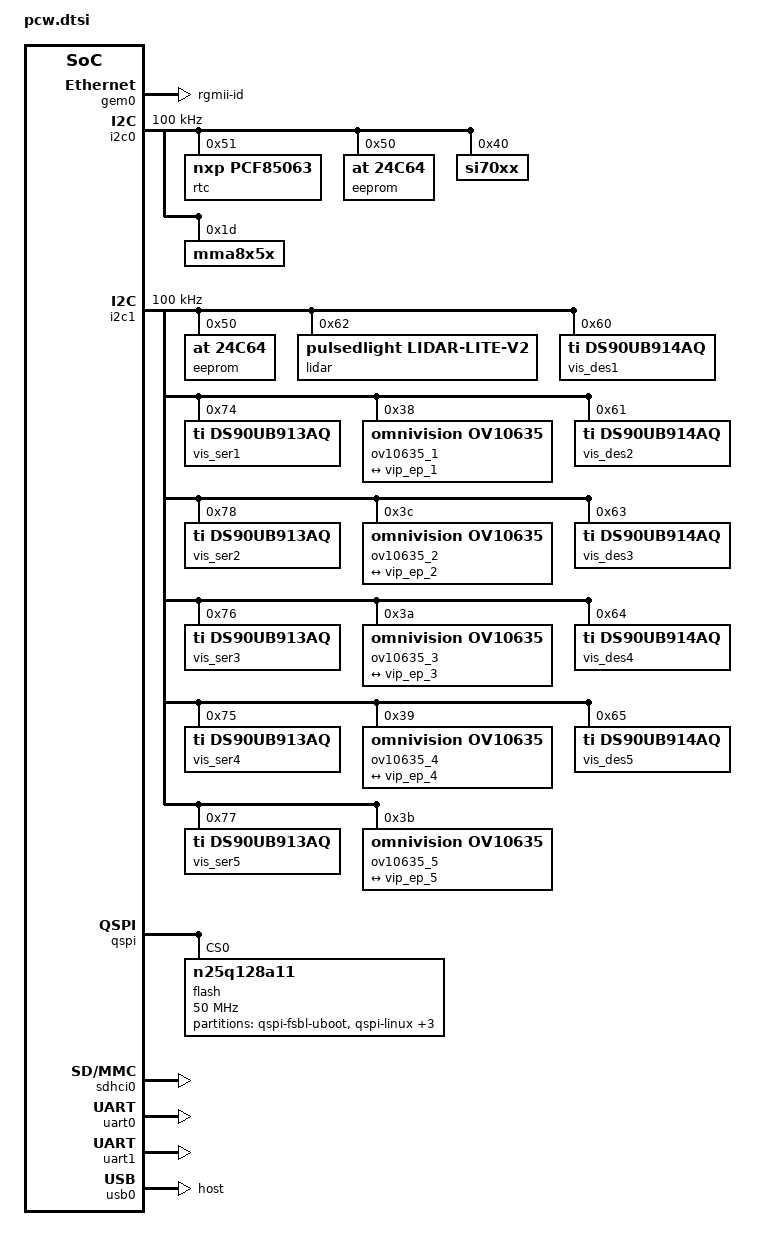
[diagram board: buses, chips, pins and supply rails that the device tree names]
/*
 * CAUTION: This file is automatically generated by Xilinx.
 * Version:  
 * Today is: Mon Aug 21 14:07:54 2017
*/


/ {
	cpus {
		cpu@0 {
			operating-points = <800000 1000000 400000 1000000 200000 1000000>;
		};
	};
};

&gem0 {
	enet-reset = <&gpio0 51 0>;
	phy-mode = "rgmii-id";
	status = "okay";
	xlnx,ptp-enet-clock = <0x7f28150>;
};

&gpio0 {
	emio-gpio-width = <64>;
	gpio-mask-high = <0x0>;
	gpio-mask-low = <0x5600>;
};

&i2c0 {
	status = "okay";
	clock-frequency = <100000>;
	
	rtc@51 {
                compatible = "nxp,pcf85063";
                reg = <0x51>;
        };
	
	eeprom@50 {
                compatible = "at,24c64";
                reg = <0x50>;
        };
	
	si70xx: si70xx@40 {
                compatible = "si70xx";
                reg = <0x40>;
        };
	
	mma8x5x: mma8x5x@1d {
                compatible = "mma8x5x";
                reg = <0x1d>;		
        };
};

&i2c1 {
	clock-frequency = <100000>;
	status = "okay";
	
	eeprom@50 {
                compatible = "at,24c64";
                reg = <0x50>;
        };
	
	lidar: lidar-lite-v2@62 {
		compatible = "pulsedlight,lidar-lite-v2";
		reg = <0x62>;
	};
	
	vis_des1: ds90ub914aq@60 {
		compatible = "ti,ds90ub914aq";
		reg = <0x60>;
	};

	vis_ser1: ds90ub913aq@74 {
		compatible = "ti,ds90ub913aq";
		reg = <0x74>;
	};
	
	ov10635_1: ov10635@38 {
		compatible = "omnivision,ov10635";
		reg = <0x38>;
		deserializer = <&vis_des1>;
		serializer = <&vis_ser1>;

		port {
		      ov10635_ep_1: endpoint {
			      remote-endpoint = <&vip_ep_1>;      
		      };
		};
	};
	
	
	vis_des2: ds90ub914aq@61 {
		compatible = "ti,ds90ub914aq";
		reg = <0x61>;
	};

	vis_ser2: ds90ub913aq@78 {
		compatible = "ti,ds90ub913aq";
		reg = <0x78>;
	};
	
	ov10635_2: ov10635@3C {
		compatible = "omnivision,ov10635";
		reg = <0x3C>;
		deserializer = <&vis_des2>;
		serializer = <&vis_ser2>;

		port {
		      ov10635_ep_2: endpoint {
			      remote-endpoint = <&vip_ep_2>;      
		      };
		};
	};
	
	
	vis_des3: ds90ub914aq@63 {
		compatible = "ti,ds90ub914aq";
		reg = <0x63>;
	};

	vis_ser3: ds90ub913aq@76 {
		compatible = "ti,ds90ub913aq";
		reg = <0x76>;
	};
	
	ov10635_3: ov10635@3A {
		compatible = "omnivision,ov10635";
		reg = <0x3A>;
		deserializer = <&vis_des3>;
		serializer = <&vis_ser3>;

		port {
		      ov10635_ep_3: endpoint {
			      remote-endpoint = <&vip_ep_3>;      
		      };
		};
	};
	
	
	vis_des4: ds90ub914aq@64 {
		compatible = "ti,ds90ub914aq";
		reg = <0x64>;
	};

	vis_ser4: ds90ub913aq@75 {
		compatible = "ti,ds90ub913aq";
		reg = <0x75>;
	};
	
	ov10635_4: ov10635@39 {
		compatible = "omnivision,ov10635";
		reg = <0x39>;
		deserializer = <&vis_des4>;
		serializer = <&vis_ser4>;

		port {
		      ov10635_ep_4: endpoint {
			      remote-endpoint = <&vip_ep_4>;      
		      };
		};
	};
	
	
	vis_des5: ds90ub914aq@65 {
		compatible = "ti,ds90ub914aq";
		reg = <0x65>;
	};

	vis_ser5: ds90ub913aq@77 {
		compatible = "ti,ds90ub913aq";
		reg = <0x77>;
	};
	
	ov10635_5: ov10635@3B {
		compatible = "omnivision,ov10635";
		reg = <0x3B>;
		deserializer = <&vis_des5>;
		serializer = <&vis_ser5>;

		port {
		      ov10635_ep_5: endpoint {
			      remote-endpoint = <&vip_ep_5>;      
		      };
		};
	};
};

&intc {
	num_cpus = <2>;
	num_interrupts = <96>;
};

&qspi {
	is-dual = <0>;
	num-cs = <1>;
	status = "okay";
	#address-cells = <1>;
	#size-cells = <0>;
	flash@0 {
              compatible = "n25q128a11";
              reg = <0x0>;
              spi-tx-bus-width = <1>;
              spi-rx-bus-width = <4>;
              spi-max-frequency = <50000000>;
              #address-cells = <1>;
              #size-cells = <1>;
              partition@qspi-fsbl-uboot {
                        label = "qspi-fsbl-uboot";
                        reg = <0x0 0x100000>;
              };
              partition@qspi-linux {
                        label = "qspi-linux";
                        reg = <0x100000 0x500000>;
              };
              partition@qspi-device-tree {
                        label = "qspi-device-tree";
                        reg = <0x600000 0x20000>;
              };
              partition@qspi-rootfs {
                        label = "qspi-rootfs";
                        reg = <0x620000 0x5E0000>;
              };
              partition@qspi-bitstream {
                        label = "qspi-bitstream";
                        reg = <0xC00000 0x400000>;
              };
      };
};

&sdhci0 {
	status = "okay";
	xlnx,has-cd = <0x1>;
	xlnx,has-power = <0x0>;
	xlnx,has-wp = <0x0>;
};

&uart0 {
	device_type = "serial";
	port-number = <0>;
	status = "okay";
};

&uart1 {
	device_type = "serial";
	port-number = <1>;
	status = "okay";
};

&usb0 {
	dr_mode = "host";
	phy_type = "ulpi";
	status = "okay";
	usb-reset = <&gpio0 9 0>;
};

&clkc {
	fclk-enable = <0xf>;
	ps-clk-frequency = <50000000>;
};
